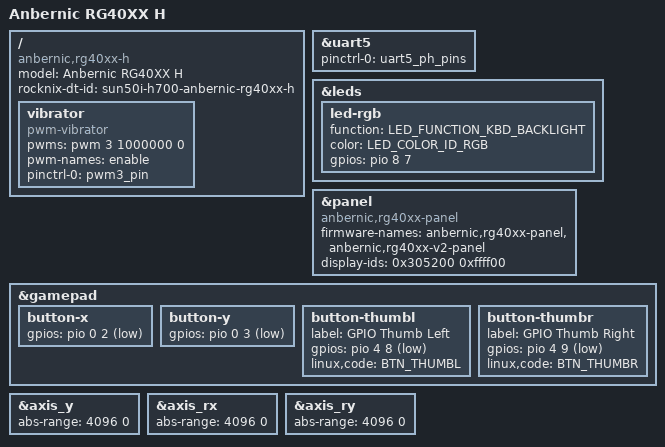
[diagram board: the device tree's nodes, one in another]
// SPDX-License-Identifier: (GPL-2.0-only OR BSD-2-Clause)
/*
 * Copyright (C) 2024 Philippe Simons <simons.philippe@gmail.com>.
 */

#include "sun50i-h700-anbernic-rg35xx-plus.dts"
#include "sun50i-h700-anbernic-sticks.dtsi"

/ {
	model = "Anbernic RG40XX H";
	compatible = "anbernic,rg40xx-h", "allwinner,sun50i-h700";
	rocknix-dt-id = "sun50i-h700-anbernic-rg40xx-h";
};


&uart5 {
	pinctrl-names = "default";
	pinctrl-0 = <&uart5_ph_pins>;
	status = "okay";
};

&leds {
	led-rgb {
		function = LED_FUNCTION_KBD_BACKLIGHT;
		color = <LED_COLOR_ID_RGB>;
		gpios = <&pio 8 7 GPIO_ACTIVE_HIGH>; /* PI7 */
	};
};

&panel {
	compatible = "anbernic,rg40xx-panel", "panel-mipi-dpi-spi";
	/* The original (FOG) panel by its ID, else the BOE ("v2") one */
	firmware-names = "anbernic,rg40xx-panel", "anbernic,rg40xx-v2-panel";
	display-ids = <0x305200 0xffff00>;
};

/* Stock; L3, R3 on PE8, PE9 as in the RG35XX H */
&gamepad {
	/* X and Y wired as on the SP */
	button-x { gpios = <&pio 0 2 GPIO_ACTIVE_LOW>; }; /* PA2 */
	button-y { gpios = <&pio 0 3 GPIO_ACTIVE_LOW>; }; /* PA3 */

	button-thumbl {
		label = "GPIO Thumb Left";
		gpios = <&pio 4 8 GPIO_ACTIVE_LOW>; /* PE8 */
		linux,code = <BTN_THUMBL>;
	};

	button-thumbr {
		label = "GPIO Thumb Right";
		gpios = <&pio 4 9 GPIO_ACTIVE_LOW>; /* PE9 */
		linux,code = <BTN_THUMBR>;
	};
};

/* Every axis reads low pushed right or down */
&axis_y { abs-range = <4096 0>; };
&axis_rx { abs-range = <4096 0>; };
&axis_ry { abs-range = <4096 0>; };

/ {
	vibrator {
		compatible = "pwm-vibrator";
		pwms = <&pwm 3 1000000 0>;
		pwm-names = "enable";
		pinctrl-0 = <&pwm3_pin>;
		pinctrl-names = "default";
	};
};
